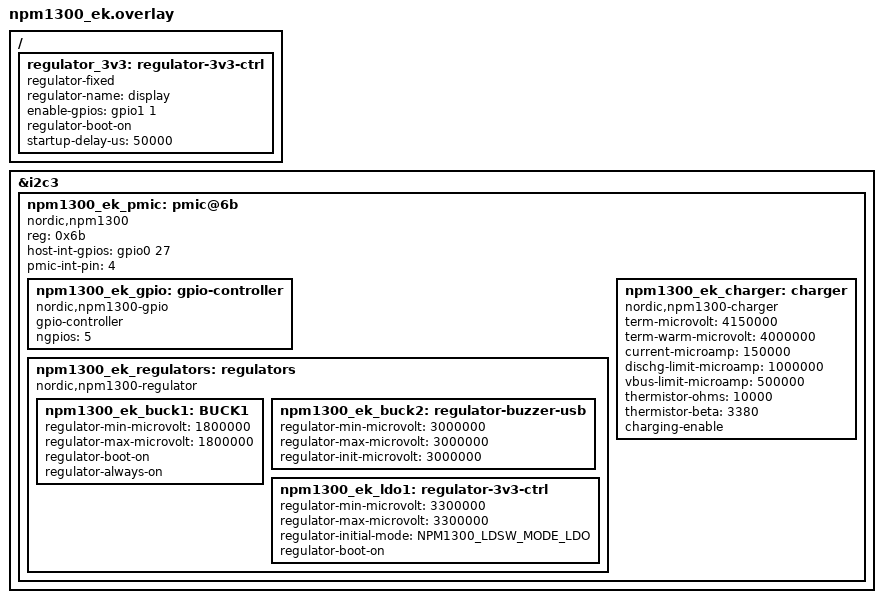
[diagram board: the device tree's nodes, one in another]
/*
 * Copyright (C) 2023 Nordic Semiconductor ASA
 * SPDX-License-Identifier: Apache-2.0
 */

 #include <dt-bindings/regulator/npm1300.h>
 #include <zephyr/dt-bindings/input/input-event-codes.h>

 / {
	regulator_3v3: regulator-3v3-ctrl {
        compatible = "regulator-fixed";
        regulator-name = "display";
        enable-gpios = <&gpio1 1 GPIO_ACTIVE_HIGH>;
        regulator-boot-on;
        startup-delay-us = <50000>;
    };
 };
 
 &i2c3 {
	 status = "okay";
	 npm1300_ek_pmic: pmic@6b {
		 compatible = "nordic,npm1300";
		 reg = <0x6b>;
		 host-int-gpios = <&gpio0 27 GPIO_ACTIVE_HIGH>;
		 pmic-int-pin	= <4>;
 
		 npm1300_ek_gpio: gpio-controller {
			 compatible = "nordic,npm1300-gpio";
			 gpio-controller;
			 #gpio-cells = <2>;
			 ngpios = <5>;
		 };
 
		 npm1300_ek_regulators: regulators {
			 compatible = "nordic,npm1300-regulator";
 
			 npm1300_ek_buck1: BUCK1 {
				 regulator-min-microvolt = <1800000>;
				 regulator-max-microvolt = <1800000>;
				 regulator-boot-on;
				 regulator-always-on;
			 };
 
			 npm1300_ek_buck2: regulator-buzzer-usb {
				 regulator-min-microvolt = <3000000>;
				 regulator-max-microvolt = <3000000>;
				 regulator-init-microvolt = <3000000>;
			 };
 
			 npm1300_ek_ldo1: regulator-3v3-ctrl {
				 regulator-min-microvolt = <3300000>;
				 regulator-max-microvolt = <3300000>;
				 regulator-initial-mode = <NPM1300_LDSW_MODE_LDO>;
				 regulator-boot-on;
			 };

			 // LDO2 is not used
		 };
 
		 npm1300_ek_charger: charger {
			 compatible = "nordic,npm1300-charger";
			 term-microvolt = <4150000>;
			 term-warm-microvolt = <4000000>;
			 current-microamp = <150000>;
			 dischg-limit-microamp = <1000000>;
			 vbus-limit-microamp = <500000>;
			 thermistor-ohms = <10000>;
			 thermistor-beta = <3380>;
			 charging-enable;
		 };
		/*
		 npm1300_ek_buttons: buttons {
			 compatible = "gpio-keys";
			 pmic_button0: pmic_button_0 {
				 gpios = < &npm1300_ek_gpio 0 GPIO_ACTIVE_HIGH>;
				 label = "Pmic button switch 0";
			 zephyr,code = <INPUT_KEY_0>;
			 };
		 };*/
	 };
 };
